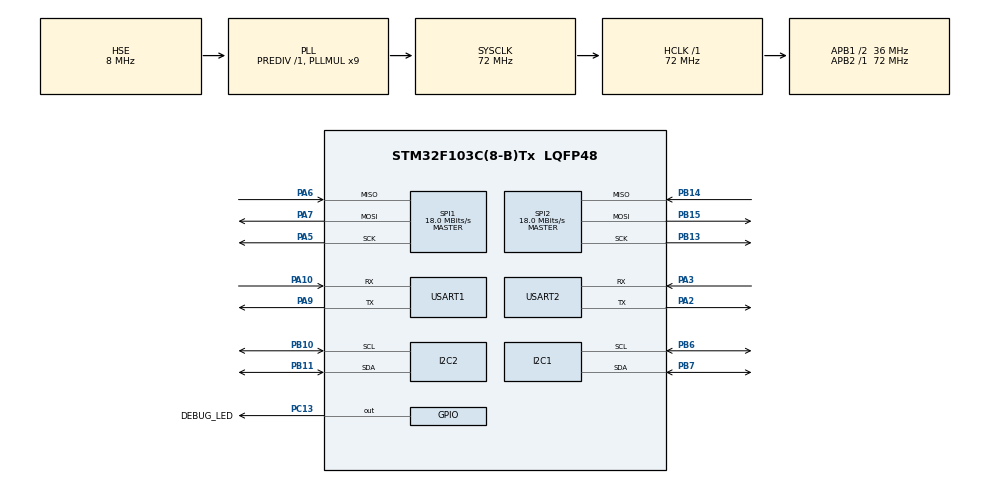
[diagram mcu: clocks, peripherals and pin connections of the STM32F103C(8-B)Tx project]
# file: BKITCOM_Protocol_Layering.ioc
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Mcu.Family=STM32F1
Mcu.Name=STM32F103C(8-B)Tx
Mcu.Package=LQFP48
NVIC.I2C1_EV_IRQn=true\:0\:0\:false\:false\:true\:true\:true\:true
NVIC.I2C2_EV_IRQn=true\:0\:0\:false\:false\:true\:true\:true\:true
NVIC.PriorityGroup=NVIC_PRIORITYGROUP_4
NVIC.SPI1_IRQn=true\:0\:0\:false\:false\:true\:true\:true\:true
NVIC.SPI2_IRQn=true\:0\:0\:false\:false\:true\:true\:true\:true
NVIC.TIM2_IRQn=true\:0\:0\:false\:false\:true\:true\:true\:true
NVIC.USART1_IRQn=true\:0\:0\:false\:false\:true\:true\:true\:true
NVIC.USART2_IRQn=true\:0\:0\:false\:false\:true\:true\:true\:true
PA10.Mode=Asynchronous
PA10.Signal=USART1_RX
PA13.Mode=Serial_Wire
PA13.Signal=SYS_JTMS-SWDIO
PA14.Mode=Serial_Wire
PA14.Signal=SYS_JTCK-SWCLK
PA2.Mode=Asynchronous
PA2.Signal=USART2_TX
PA3.Mode=Asynchronous
PA3.Signal=USART2_RX
PA5.Mode=Full_Duplex_Master
PA5.Signal=SPI1_SCK
PA6.Mode=Full_Duplex_Master
PA6.Signal=SPI1_MISO
PA7.Mode=Full_Duplex_Master
PA7.Signal=SPI1_MOSI
PA9.Mode=Asynchronous
PA9.Signal=USART1_TX
PB10.Mode=I2C
PB10.Signal=I2C2_SCL
PB11.Mode=I2C
PB11.Signal=I2C2_SDA
PB13.Mode=Full_Duplex_Master
PB13.Signal=SPI2_SCK
PB14.Mode=Full_Duplex_Master
PB14.Signal=SPI2_MISO
PB15.Mode=Full_Duplex_Master
PB15.Signal=SPI2_MOSI
PB6.Mode=I2C
PB6.Signal=I2C1_SCL
PB7.Mode=I2C
PB7.Signal=I2C1_SDA
PC13-TAMPER-RTC.GPIO_Label=DEBUG_LED
PC13-TAMPER-RTC.PinState=GPIO_PIN_SET
PC13-TAMPER-RTC.Signal=GPIO_Output
PD0-OSC_IN.Mode=HSE-External-Oscillator
PD0-OSC_IN.Signal=RCC_OSC_IN
PD1-OSC_OUT.Mode=HSE-External-Oscillator
PD1-OSC_OUT.Signal=RCC_OSC_OUT
ProjectManager.HeapSize=0x200
ProjectManager.StackSize=0x400
ProjectManager.TargetToolchain=STM32CubeIDE
RCC.AHBFreq_Value=72000000
RCC.APB1CLKDivider=RCC_HCLK_DIV2
RCC.APB1Freq_Value=36000000
RCC.APB1TimFreq_Value=72000000
RCC.APB2Freq_Value=72000000
RCC.APB2TimFreq_Value=72000000
RCC.HCLKFreq_Value=72000000
RCC.PLLMUL=RCC_PLL_MUL9
RCC.PLLSourceVirtual=RCC_PLLSOURCE_HSE
RCC.SYSCLKFreq_VALUE=72000000
RCC.SYSCLKSource=RCC_SYSCLKSOURCE_PLLCLK
RCC.USBFreq_Value=72000000
SPI1.BaudRatePrescaler=SPI_BAUDRATEPRESCALER_4
SPI1.CalculateBaudRate=18.0 MBits/s
SPI1.Direction=SPI_DIRECTION_2LINES
SPI1.Mode=SPI_MODE_MASTER
SPI1.VirtualType=VM_MASTER
SPI2.BaudRatePrescaler=SPI_BAUDRATEPRESCALER_2
SPI2.CalculateBaudRate=18.0 MBits/s
SPI2.Direction=SPI_DIRECTION_2LINES
SPI2.Mode=SPI_MODE_MASTER
SPI2.VirtualType=VM_MASTER
TIM2.Period=1
TIM2.Prescaler=35999
USART1.VirtualMode=VM_ASYNC
USART2.VirtualMode=VM_ASYNC
VP_TIM2_VS_ClockSourceINT.Mode=Internal
board=custom

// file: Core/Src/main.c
/* USER CODE BEGIN Header */
/**
  ******************************************************************************
  * @file           : main.c
  * @brief          : Main program body
  ******************************************************************************
  * @attention
  *
  * Copyright (c) 2025 STMicroelectronics.
  * All rights reserved.
  *
  * This software is licensed under terms that can be found in the LICENSE file
  * in the root directory of this software component.
  * If no LICENSE file comes with this software, it is provided AS-IS.
  *
  ******************************************************************************
  */
/* USER CODE END Header */
#include "main.h"

/* USER CODE BEGIN Includes */
//#include "Oled_Display.h"
#include "Hardware_Interface_Layer.h"
/* USER CODE END Includes */

I2C_HandleTypeDef hi2c1;
I2C_HandleTypeDef hi2c2;

SPI_HandleTypeDef hspi1;
SPI_HandleTypeDef hspi2;

TIM_HandleTypeDef htim2;

UART_HandleTypeDef huart1;
UART_HandleTypeDef huart2;

void SystemClock_Config(void);
static void MX_GPIO_Init(void);
static void MX_I2C1_Init(void);
static void MX_I2C2_Init(void);
static void MX_SPI1_Init(void);
static void MX_SPI2_Init(void);
static void MX_USART1_UART_Init(void);
static void MX_USART2_UART_Init(void);
static void MX_TIM2_Init(void);

int main(void)
{

  /* MCU Configuration--------------------------------------------------------*/

  /* Reset of all peripherals, Initializes the Flash interface and the Systick. */
  HAL_Init();

  /* Configure the system clock */
  SystemClock_Config();

  /* Initialize all configured peripherals */
  MX_GPIO_Init();
  MX_I2C1_Init();
  MX_I2C2_Init();
  MX_SPI1_Init();
  MX_SPI2_Init();
  MX_USART1_UART_Init();
  MX_USART2_UART_Init();
  MX_TIM2_Init();
  /* USER CODE BEGIN 2 */

  uart_config(1, 9600, BKITCOM_SLAVE);
  hw_init();
//  hw_send(I2C, 0x05, data, sizeof(data)/sizeof(data[0]));
  /* USER CODE END 2 */

  /* Infinite loop */
  while (1)
  {
	 if (Received_Flag == 1) {
		 HAL_GPIO_WritePin(DEBUG_LED_GPIO_Port, DEBUG_LED_Pin, 0);
	 } else {
		 HAL_GPIO_WritePin(DEBUG_LED_GPIO_Port, DEBUG_LED_Pin, 1);
	 }
  }
}

void SystemClock_Config(void)
{
  RCC_OscInitTypeDef RCC_OscInitStruct = {0};
  RCC_ClkInitTypeDef RCC_ClkInitStruct = {0};

  /** Initializes the RCC Oscillators according to the specified parameters
  * in the RCC_OscInitTypeDef structure.
  */
  RCC_OscInitStruct.OscillatorType = RCC_OSCILLATORTYPE_HSE;
  RCC_OscInitStruct.HSEState = RCC_HSE_ON;
  RCC_OscInitStruct.HSEPredivValue = RCC_HSE_PREDIV_DIV1;
  RCC_OscInitStruct.HSIState = RCC_HSI_ON;
  RCC_OscInitStruct.PLL.PLLState = RCC_PLL_ON;
  RCC_OscInitStruct.PLL.PLLSource = RCC_PLLSOURCE_HSE;
  RCC_OscInitStruct.PLL.PLLMUL = RCC_PLL_MUL9;
  if (HAL_RCC_OscConfig(&RCC_OscInitStruct) != HAL_OK)
  {
    Error_Handler();
  }

  /** Initializes the CPU, AHB and APB buses clocks
  */
  RCC_ClkInitStruct.ClockType = RCC_CLOCKTYPE_HCLK|RCC_CLOCKTYPE_SYSCLK
                              |RCC_CLOCKTYPE_PCLK1|RCC_CLOCKTYPE_PCLK2;
  RCC_ClkInitStruct.SYSCLKSource = RCC_SYSCLKSOURCE_PLLCLK;
  RCC_ClkInitStruct.AHBCLKDivider = RCC_SYSCLK_DIV1;
  RCC_ClkInitStruct.APB1CLKDivider = RCC_HCLK_DIV2;
  RCC_ClkInitStruct.APB2CLKDivider = RCC_HCLK_DIV1;

  if (HAL_RCC_ClockConfig(&RCC_ClkInitStruct, FLASH_LATENCY_2) != HAL_OK)
  {
    Error_Handler();
  }
}

static void MX_I2C1_Init(void)
{

  hi2c1.Instance = I2C1;
  hi2c1.Init.ClockSpeed = 100000;
  hi2c1.Init.DutyCycle = I2C_DUTYCYCLE_2;
  hi2c1.Init.OwnAddress1 = 0;
  hi2c1.Init.AddressingMode = I2C_ADDRESSINGMODE_7BIT;
  hi2c1.Init.DualAddressMode = I2C_DUALADDRESS_DISABLE;
  hi2c1.Init.OwnAddress2 = 0;
  hi2c1.Init.GeneralCallMode = I2C_GENERALCALL_DISABLE;
  hi2c1.Init.NoStretchMode = I2C_NOSTRETCH_DISABLE;
  if (HAL_I2C_Init(&hi2c1) != HAL_OK)
  {
    Error_Handler();
  }

}

static void MX_I2C2_Init(void)
{

  hi2c2.Instance = I2C2;
  hi2c2.Init.ClockSpeed = 100000;
  hi2c2.Init.DutyCycle = I2C_DUTYCYCLE_2;
  hi2c2.Init.OwnAddress1 = 0;
  hi2c2.Init.AddressingMode = I2C_ADDRESSINGMODE_7BIT;
  hi2c2.Init.DualAddressMode = I2C_DUALADDRESS_DISABLE;
  hi2c2.Init.OwnAddress2 = 0;
  hi2c2.Init.GeneralCallMode = I2C_GENERALCALL_DISABLE;
  hi2c2.Init.NoStretchMode = I2C_NOSTRETCH_DISABLE;
  if (HAL_I2C_Init(&hi2c2) != HAL_OK)
  {
    Error_Handler();
  }

}

static void MX_SPI1_Init(void)
{

  /* SPI1 parameter configuration*/
  hspi1.Instance = SPI1;
  hspi1.Init.Mode = SPI_MODE_MASTER;
  hspi1.Init.Direction = SPI_DIRECTION_2LINES;
  hspi1.Init.DataSize = SPI_DATASIZE_8BIT;
  hspi1.Init.CLKPolarity = SPI_POLARITY_LOW;
  hspi1.Init.CLKPhase = SPI_PHASE_1EDGE;
  hspi1.Init.NSS = SPI_NSS_SOFT;
  hspi1.Init.BaudRatePrescaler = SPI_BAUDRATEPRESCALER_4;
  hspi1.Init.FirstBit = SPI_FIRSTBIT_MSB;
  hspi1.Init.TIMode = SPI_TIMODE_DISABLE;
  hspi1.Init.CRCCalculation = SPI_CRCCALCULATION_DISABLE;
  hspi1.Init.CRCPolynomial = 10;
  if (HAL_SPI_Init(&hspi1) != HAL_OK)
  {
    Error_Handler();
  }

}

static void MX_SPI2_Init(void)
{

  /* SPI2 parameter configuration*/
  hspi2.Instance = SPI2;
  hspi2.Init.Mode = SPI_MODE_MASTER;
  hspi2.Init.Direction = SPI_DIRECTION_2LINES;
  hspi2.Init.DataSize = SPI_DATASIZE_8BIT;
  hspi2.Init.CLKPolarity = SPI_POLARITY_LOW;
  hspi2.Init.CLKPhase = SPI_PHASE_1EDGE;
  hspi2.Init.NSS = SPI_NSS_SOFT;
  hspi2.Init.BaudRatePrescaler = SPI_BAUDRATEPRESCALER_2;
  hspi2.Init.FirstBit = SPI_FIRSTBIT_MSB;
  hspi2.Init.TIMode = SPI_TIMODE_DISABLE;
  hspi2.Init.CRCCalculation = SPI_CRCCALCULATION_DISABLE;
  hspi2.Init.CRCPolynomial = 10;
  if (HAL_SPI_Init(&hspi2) != HAL_OK)
  {
    Error_Handler();
  }

}

static void MX_TIM2_Init(void)
{

  TIM_ClockConfigTypeDef sClockSourceConfig = {0};
  TIM_MasterConfigTypeDef sMasterConfig = {0};

  htim2.Instance = TIM2;
  htim2.Init.Prescaler = 35999;
  htim2.Init.CounterMode = TIM_COUNTERMODE_UP;
  htim2.Init.Period = 1;
  htim2.Init.ClockDivision = TIM_CLOCKDIVISION_DIV1;
  htim2.Init.AutoReloadPreload = TIM_AUTORELOAD_PRELOAD_DISABLE;
  if (HAL_TIM_Base_Init(&htim2) != HAL_OK)
  {
    Error_Handler();
  }
  sClockSourceConfig.ClockSource = TIM_CLOCKSOURCE_INTERNAL;
  if (HAL_TIM_ConfigClockSource(&htim2, &sClockSourceConfig) != HAL_OK)
  {
    Error_Handler();
  }
  sMasterConfig.MasterOutputTrigger = TIM_TRGO_RESET;
  sMasterConfig.MasterSlaveMode = TIM_MASTERSLAVEMODE_DISABLE;
  if (HAL_TIMEx_MasterConfigSynchronization(&htim2, &sMasterConfig) != HAL_OK)
  {
    Error_Handler();
  }

}

static void MX_USART1_UART_Init(void)
{

  huart1.Instance = USART1;
  huart1.Init.BaudRate = 115200;
  huart1.Init.WordLength = UART_WORDLENGTH_8B;
  huart1.Init.StopBits = UART_STOPBITS_1;
  huart1.Init.Parity = UART_PARITY_NONE;
  huart1.Init.Mode = UART_MODE_TX_RX;
  huart1.Init.HwFlowCtl = UART_HWCONTROL_NONE;
  huart1.Init.OverSampling = UART_OVERSAMPLING_16;
  if (HAL_UART_Init(&huart1) != HAL_OK)
  {
    Error_Handler();
  }

}

static void MX_USART2_UART_Init(void)
{

  huart2.Instance = USART2;
  huart2.Init.BaudRate = 115200;
  huart2.Init.WordLength = UART_WORDLENGTH_8B;
  huart2.Init.StopBits = UART_STOPBITS_1;
  huart2.Init.Parity = UART_PARITY_NONE;
  huart2.Init.Mode = UART_MODE_TX_RX;
  huart2.Init.HwFlowCtl = UART_HWCONTROL_NONE;
  huart2.Init.OverSampling = UART_OVERSAMPLING_16;
  if (HAL_UART_Init(&huart2) != HAL_OK)
  {
    Error_Handler();
  }

}

static void MX_GPIO_Init(void)
{
  GPIO_InitTypeDef GPIO_InitStruct = {0};

  /* GPIO Ports Clock Enable */
  __HAL_RCC_GPIOC_CLK_ENABLE();
  __HAL_RCC_GPIOD_CLK_ENABLE();
  __HAL_RCC_GPIOA_CLK_ENABLE();
  __HAL_RCC_GPIOB_CLK_ENABLE();

  /*Configure GPIO pin Output Level */
  HAL_GPIO_WritePin(DEBUG_LED_GPIO_Port, DEBUG_LED_Pin, GPIO_PIN_SET);

  /*Configure GPIO pin : DEBUG_LED_Pin */
  GPIO_InitStruct.Pin = DEBUG_LED_Pin;
  GPIO_InitStruct.Mode = GPIO_MODE_OUTPUT_PP;
  GPIO_InitStruct.Pull = GPIO_NOPULL;
  GPIO_InitStruct.Speed = GPIO_SPEED_FREQ_LOW;
  HAL_GPIO_Init(DEBUG_LED_GPIO_Port, &GPIO_InitStruct);

}

void Error_Handler(void)
{
  __disable_irq();
  while (1)
  {
  }
}
